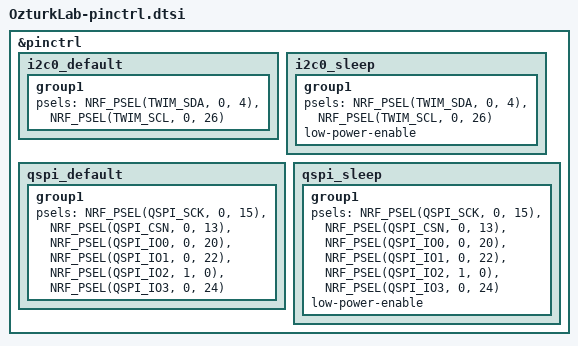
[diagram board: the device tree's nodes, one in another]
&pinctrl {
	
	i2c0_default: i2c0_default {
		group1 {
			psels = <NRF_PSEL(TWIM_SDA, 0, 4)>,
				<NRF_PSEL(TWIM_SCL, 0, 26)>;
		};
	};

	i2c0_sleep: i2c0_sleep {
		group1 {
			psels = <NRF_PSEL(TWIM_SDA, 0, 4)>,
				<NRF_PSEL(TWIM_SCL, 0, 26)>;
			low-power-enable;
		};
	};


	/* MX25R6435F external flash */
	qspi_default: qspi_default {
		group1 {
			psels = <NRF_PSEL(QSPI_SCK, 0, 15)>,
				<NRF_PSEL(QSPI_CSN, 0, 13)>,
				<NRF_PSEL(QSPI_IO0, 0, 20)>,
				<NRF_PSEL(QSPI_IO1, 0, 22)>,
				<NRF_PSEL(QSPI_IO2, 1, 0)>,
				<NRF_PSEL(QSPI_IO3, 0, 24)>;
		};
	};

	qspi_sleep: qspi_sleep {
		group1 {
			psels = <NRF_PSEL(QSPI_SCK, 0, 15)>,
				<NRF_PSEL(QSPI_CSN, 0, 13)>,
				<NRF_PSEL(QSPI_IO0, 0, 20)>,
				<NRF_PSEL(QSPI_IO1, 0, 22)>,
				<NRF_PSEL(QSPI_IO2, 1, 0)>,
				<NRF_PSEL(QSPI_IO3, 0, 24)>;
			low-power-enable;
		};
	};
};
